# max32572 register map
Vendor: Maxim-Integrated; Series: ARMCM4; File version: 1.0
CPU: CM4 r2p1, little endian, MPU, FPU, 3 interrupt priority bits
Registers are 32-bit, read-write, reset 0x0 unless marked. A register's access mark holds for its fields unless they carry their own. Offsets are from the block's base; [hi:lo] are bit positions.

## FCR — Function Control Register.
Base 0x40000800
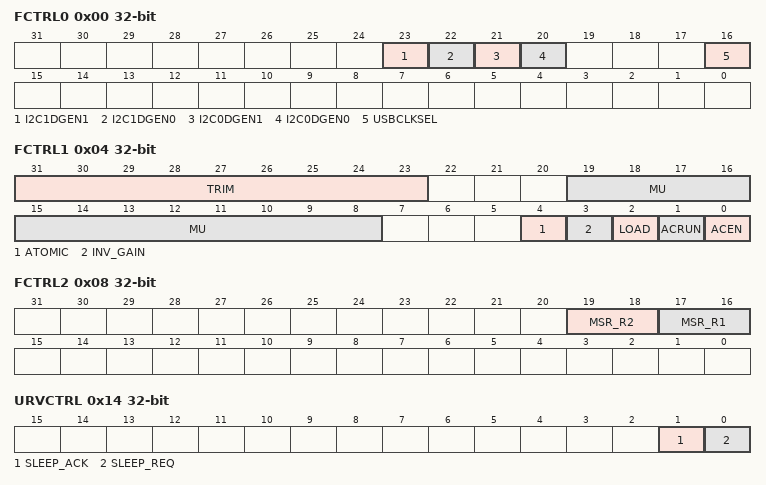
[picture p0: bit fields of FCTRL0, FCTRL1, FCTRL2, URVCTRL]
0x00 FCTRL0 — Register 0.
  [23] I2C1DGEN1 — I2C1 SCL Glitch Filter Enable.
    0=dis (Filter disabled.); 1=en (Filter enabled.)
  [22] I2C1DGEN0 — I2C1 SDA Glitch Filter Enable.
    0=dis (Filter disabled.); 1=en (Filter enabled.)
  [21] I2C0DGEN1 — I2C0 SCL Glitch Filter Enable.
    0=dis (Filter disabled.); 1=en (Filter enabled.)
  [20] I2C0DGEN0 — I2C0 SDA Glitch Filter Enable.
    0=dis (Filter disabled.); 1=en (Filter enabled.)
  [16] USBCLKSEL — USB External Core Clock Select.
    0=sys (Generated clock from system clock.); 1=dig (Digital clock from a GPIO.)
0x04 FCTRL1 — Register 1.
  [31:23] TRIM — 150MHz HFIO Auto Calibration Trim
  [19:8] MU — MU value.
  [4] ATOMIC — Atomic mode.
    0=not (Not Running.); 1=run (Running.)
  [3] INV_GAIN — Invert Gain.
    0=not (Not Running.); 1=run (Running.)
  [2] LOAD — Load Trim.
  [1] ACRUN — Autocalibration Run.
    0=not (Not Running.); 1=run (Running.)
  [0] ACEN — Auto-calibration Enable.
    0=dis (Disabled.); 1=en (Enabled.)
0x08 FCTRL2 — Register 2.
  [19:18] MSR_R2, [17:16] MSR_R1
0x0C FCTRL3 — Register 3.
  [7:0] DONECNT — Auto-calibration Done Counter Setting.
0x10 URVBOOTADDR — Register 4.
  [31:0] BOOTADDR — RISCV Boot Address.
0x14 URVCTRL — Register 5.
  [1] SLEEP_ACK — Acknowledgement of Sleep Request for RISCV.
  [0] SLEEP_REQ — Sleep Request to RISCV.
0x1C GP — General Purpose Register.
  [31:0] GP — General Purpose.

## TRIMSIR — Trim System Initilazation Registers
Base 0x40005400
0x00 rsv0 — RFU
0x08 BB_SIR2 ro — System Init. Configuration Register 2.
0x0C BB_SIR3 ro — System Init. Configuration Register 3.

## MCR — Misc Control.
Base 0x40006C00
0x00 ECCEN — ECC Enable Register
  [10] ICCXIP — IcacheXIP ECC Enable.
    0=dis (disabled.); 1=en (enabled.)
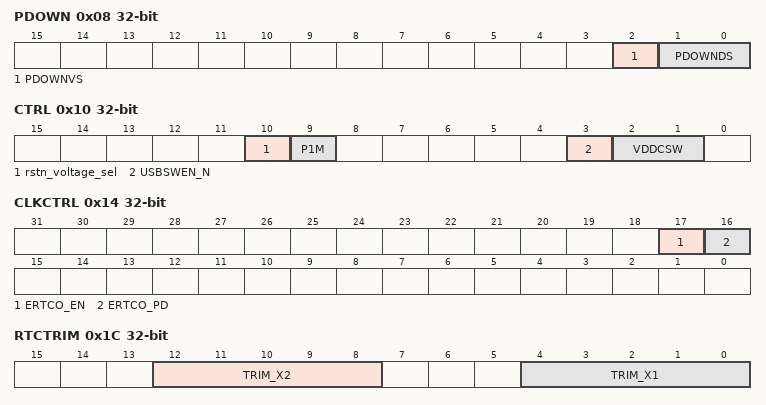
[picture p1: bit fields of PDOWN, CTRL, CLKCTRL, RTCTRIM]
0x08 PDOWN — PDOWN Drive Strength
  [2] PDOWNVS — PDOWN Voltage Select
  [1:0] PDOWNDS — PDOWN Drive Strength
0x10 CTRL — Misc Power State Control Register
  [10] rstn_voltage_sel — Error! Description not Found!
  [9] P1M — Enable the Reset Pad Pull Up Resistors
    0=1m (1MOhm Pullup); 1=25k (25kOhm Pullup.)
  [3] USBSWEN_N — USB Switch Control
    1=off (USB SW off in LP modes); 0=on (USB SW On)
  [2:1] VDDCSW — Controls switching of VCORE
0x14 CLKCTRL — Clock Control Register.
  [17] ERTCO_EN — 32kHz Crystal Oscillator Enable.
  [16] ERTCO_PD — 32kHz Crystal Oscillator Power Down.
0x18 RST — Reset Register.
  [0] RTC — Real Time Cock Reset.
0x1C RTCTRIM
  [12:8] TRIM_X2 — RTC TRIM X2
  [4:0] TRIM_X1 — RTC Trim X1
0x60 LDOCTRL — LDO Control Register.
  [0] LDO0P9_EN — LDO 0.9V Enable.

## HTMR — High Speed Timer Module.
Base 0x4001B000
Same registers: HTMR1 0x4001C000
0x00 SEC reset not defined — HTimer Long-Interval Counter. This register contains the 32 most significant bits of the counter.
  [31:0] RTS — HTimer Long Interval Counter.
0x04 SSEC reset not defined — HTimer Short Interval Counter. This counter ticks every t_htclk (16.48uS). HTIMER_SEC is incremented when this register rolls over from 0xFF to 0x00.
  [7:0] RTSS — HTimer Short Interval Counter.
0x08 RAS reset not defined — Long Interval Alarm.
  [19:0] RAS — HTimer Long Interval Alarm. An Alarm is triggered when this value matches HTIMER_SEC[19:0]
0x0C RSSA reset not defined — HTimer Short Interval Alarm. This register contains the reload value for the short interval alarm, HTIMER_CTRL.alarm_ss_fl is raised on rollover.
  [31:0] RSSA — This register contains the reload value for the short interval alarm.
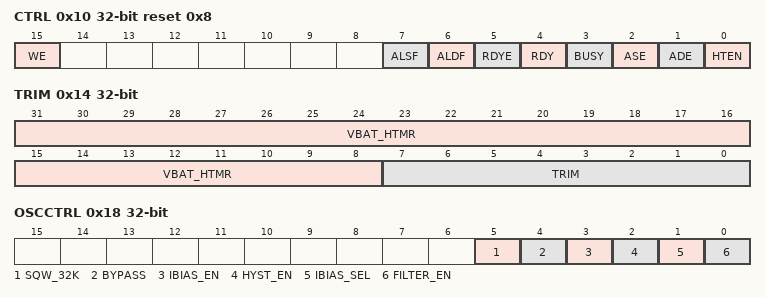
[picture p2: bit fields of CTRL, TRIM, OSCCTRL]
0x10 CTRL reset 0x8 (reset mask 0xFFFFFF38) — HTimer Control Register.
  [15] WE — Write Enable. This register bit serves as a protection mechanism against unintentional writes to critical HTimer bits.
    0=dis (Not active.); 1=en
  [7] ALSF ro — Short Interval Alarm Interrupt Flag. This alarm is qualified as wake-up source to the processor.
    0=inactive (Not active.); 1=Pending (Active.)
  [6] ALDF ro — Long Interval Alarm Interrupt Flag. This alarm is qualified as wake-up source to the processor.
    0=inactive (Not active.); 1=pending (Active.)
  [5] RDYE — HTimer Ready Interrupt Enable.
    0=dis (Disable.); 1=en (Enable.)
  [4] RDY — HTimer Ready. This bit is set to 1 by hardware when the HTimer count registers update. It can be cleared to 0 by software at any time. It will also be cleared to 0 by hardware just prior to an update of the HTimer count register.
    0=busy (Register has not updated.); 1=ready
  [3] BUSY ro — HTimer Busy. This bit is set to 1 by hardware when changes to HTimer registers required a synchronized version of the register to be in place. This bit is automatically cleared by hardware.
    0=idle; 1=busy
  [2] ASE — Short Interval Alarm Interrupt Enable. Change to this bit is effective only after BUSY is cleared from 1 to 0.
    0=dis (Disable.); 1=en (Enable.)
  [1] ADE — Long Interval Alarm Interrupt Enable. Change to this bit is effective only after BUSY is cleared from 1 to 0.
    0=dis (Disable.); 1=en (Enable.)
  [0] HTEN — HTimer Enable. This bit enables the Real Time Clock. This bit can only be written when WE=1 and BUSY =0. Change to this bit is effective only after BUSY is cleared from 1 to 0.
    0=dis (Disable.); 1=en (Enable.)
0x14 TRIM reset not defined — HTimer Trim Register.
  [31:8] VBAT_HTMR — VBAT HTimer Value. When HTMR is running off of VBAT, this field is incremented every 32 seconds.
  [7:0] TRIM — HTMR Trim. This register contains the 2's complement value that specifies the trim resolution. Each increment or decrement of the bit adds or subtracts 1ppm at each 4KHz clock value, with a maximum correction of +/- 127ppm.
0x18 OSCCTRL reset not defined — HTimer Oscillator Control Register.
  [5] SQW_32K — HTMR 32kHz Square Wave Output
    0=dis (Disable.); 1=en (Enable.)
  [4] BYPASS — HTMR Crystal Bypass
    0=dis (Disable.); 1=en (Enable.)
  [3] IBIAS_EN — HTMR IBIAS Enable.
  [2] HYST_EN — HTMR Hysteresis Enable.
  [1] IBIAS_SEL — IBIAS Select.
    0=2x; 1=4x
  [0] FILTER_EN — Enable Filter.
